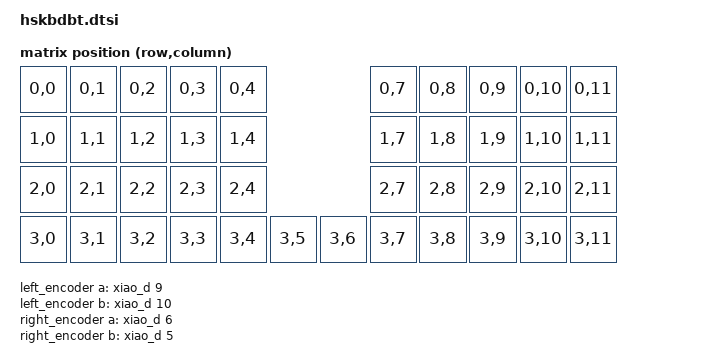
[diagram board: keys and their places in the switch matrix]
// This file was generated from a template. Edit it to match your keyboard.
// See https://zmk.dev/docs/development/hardware-integration/new-shield for more
// instructions.

#include <dt-bindings/zmk/matrix_transform.h>

#include "hskbdbt-layouts.dtsi"

/ {
    chosen {
        zmk,physical-layout = &default_layout;
    };

    kscan: kscan {
        compatible = "zmk,kscan-gpio-matrix";
        diode-direction = "col2row";
        wakeup-source;
    };

    default_transform: default_transform {
        // See https://zmk.dev/docs/development/hardware-integration/new-shield#matrix-transform
        // for how to configure this
        compatible = "zmk,matrix-transform";
        columns = <12>;
        rows = <4>;

        map = <
            RC(0, 0) RC(0, 1) RC(0, 2) RC(0, 3) RC(0, 4)                   RC(0, 7) RC(0, 8) RC(0, 9) RC(0, 10) RC(0, 11)
            RC(1, 0) RC(1, 1) RC(1, 2) RC(1, 3) RC(1, 4)                   RC(1, 7) RC(1, 8) RC(1, 9) RC(1, 10) RC(1, 11)
            RC(2, 0) RC(2, 1) RC(2, 2) RC(2, 3) RC(2, 4)                   RC(2, 7) RC(2, 8) RC(2, 9) RC(2, 10) RC(2, 11)          
            RC(3, 0) RC(3, 1) RC(3, 2) RC(3, 3) RC(3, 4) RC(3, 5) RC(3, 6) RC(3, 7) RC(3, 8) RC(3, 9) RC(3, 10) RC(3, 11)
        >;
    };

    // Encoder support (EC11) --------------------------------------------------
    left_encoder: left_encoder {
        compatible = "alps,ec11";
        a-gpios = <&xiao_d 9 (GPIO_ACTIVE_HIGH | GPIO_PULL_UP)>;
        b-gpios = <&xiao_d 10 (GPIO_ACTIVE_HIGH | GPIO_PULL_UP)>;
        steps = <68>;
           status = "disabled";
    };

    // Encoder support (EC11) --------------------------------------------------
    right_encoder: right_encoder {
        compatible = "alps,ec11";
        a-gpios = <&xiao_d 6 (GPIO_ACTIVE_HIGH | GPIO_PULL_UP)>;
        b-gpios = <&xiao_d 5 (GPIO_ACTIVE_HIGH | GPIO_PULL_UP)>;
        steps = <72>;
           status = "disabled";
    };

    // Order here must match sensor-bindings order in keymap.
    sensors: sensors {
        compatible = "zmk,keymap-sensors";
        sensors = <&left_encoder &right_encoder>;
        triggers-per-rotation = <24>;
    };
};
